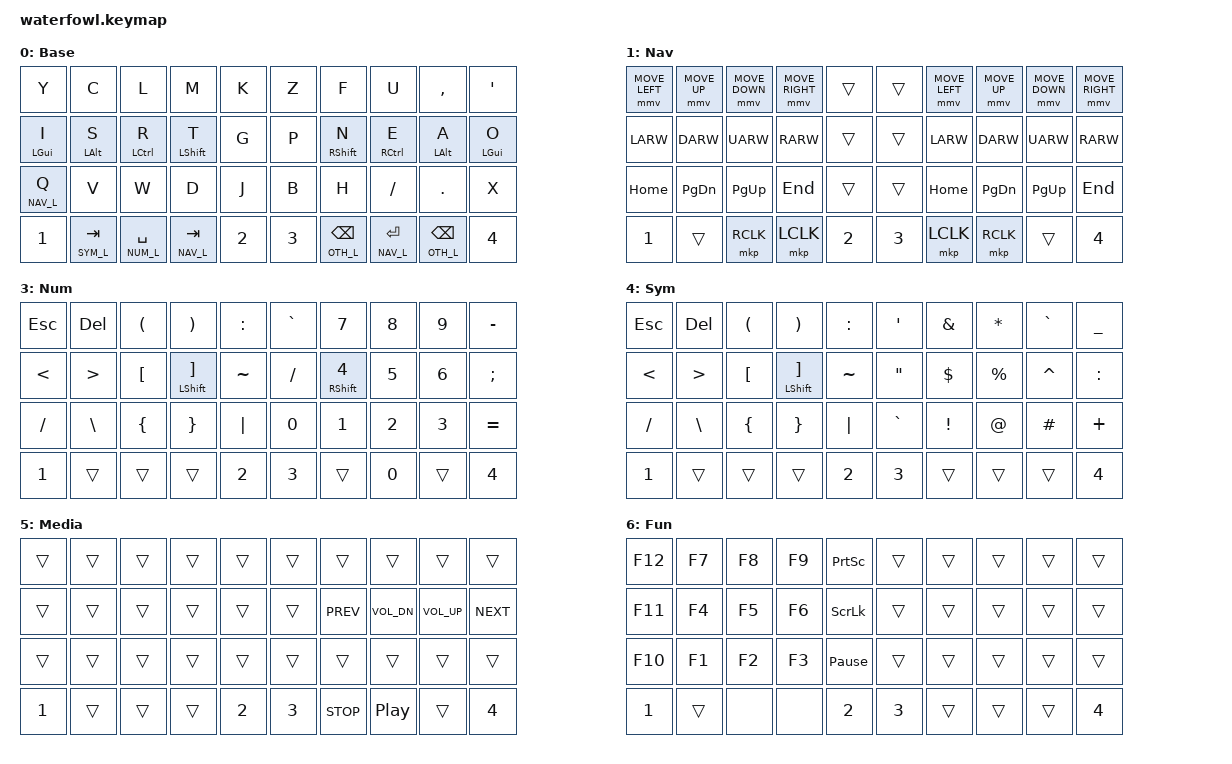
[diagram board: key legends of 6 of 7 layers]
/*
 * Copyright (c) 2022 The ZMK Contributors
 *
 * SPDX-License-Identifier: MIT
 */

#include <behaviors.dtsi>
#include <dt-bindings/zmk/keys.h>
#include <dt-bindings/zmk/bt.h>
#include <dt-bindings/zmk/outputs.h>
#include <dt-bindings/zmk/ext_power.h>
#include <dt-bindings/zmk/mouse.h>

#define NAV_L 1
#define OTH_L 2
#define NUM_L 3
#define SYM_L 4
#define MED_L 5
#define FUN_L 6

// Using layer taps on thumbs, having quick tap as well helps w/ repeating space/backspace
&lt { quick_tap_ms = <200>; };

/ {
    combos {
        compatible = "zmk,combos";

        med_mo {
	    timeout-ms = <50>;
            key-positions = <30 31>;
            bindings = <&caps_word>;
        };

        fn_mo {
	    timeout-ms = <50>;
            key-positions = <32 33>;
            bindings = <&mo FUN_L>;
        };

    };

    behaviors {
        hm: homerow_mods {
            compatible = "zmk,behavior-hold-tap";
            label = "homerow mods";
            #binding-cells = <2>;
            tapping_term_ms = <200>;
            flavor = "tap-preferred";
            bindings = <&kp>, <&kp>;
        };
    };

    keymap {
        compatible = "zmk,keymap";

        default_layer {
                label = "Base";
/* QWERTY
 *
 * ,----------------------------------.                      ,----------------------------------.
 * |   Q  |   W  |   E  |   R  |   T  |                      |   Y  |   U  |   I  |   O  |   P  |
 * |------+------+------+------+------|                      |------+------+------+------+------|
 * |   A  |   S  |   D  |   F  |   G  |                      |   H  |   J  |   K  |   L  |   ;  |
 * |------+------+------+------+------|  ,-----.    ,-----.  |------+------+------+------+------|
 * |   Z  |   X  |   C  |   V  |   B  |  |  2  |    |  3  |  |   N  |   M  |   ,  |   .  |   /  |
 * `----------------------------------'  `-----'    `-----'  `----------------------------------'
 *          ,-----.   ,--------------------.            ,--------------------.   ,-----.
 *          |  1  |   | DEL | SPACE | TAB  |            |  ESC  | BS | ENTER |   |  4  |
 *          `-----'   `--------------------'            `--------------------'   `-----'
 */
            bindings = <
                &kp Y         &kp C      &kp L       &kp M          &kp K         &kp Z            &kp F          &kp U       &kp COMMA  &kp SQT
                &hm LGUI I    &hm LALT S &hm LCTRL R &hm LSHFT T    &kp G         &kp P            &hm RSHFT N    &hm RCTRL E &hm LALT A &hm LGUI O
                &hm NAV_L Q   &kp V      &kp W       &kp D          &kp J         &kp B            &kp H          &kp FSLH    &kp DOT    &kp X
                &kp N1        &lt SYM_L TAB   &lt NUM_L SPACE  &lt NAV_L TAB &kp N2 &kp N3 &lt OTH_L BKSP  &lt NAV_L RET   &lt OTH_L BKSP &kp N4
            >;
            sensor-bindings = <&inc_dec_kp PAGE_UP PAGE_DOWN &inc_dec_kp TAB LS(TAB)>;
        };
        nav_layer {
                label = "Nav";
            bindings = <
                &mmv MOVE_LEFT  &mmv MOVE_UP  &mmv MOVE_DOWN  &mmv MOVE_RIGHT  &trans       &trans    &mmv MOVE_LEFT   &mmv MOVE_UP   &mmv MOVE_DOWN  &mmv MOVE_RIGHT
                &kp LARW        &kp DARW      &kp UARW        &kp RARW         &trans       &trans    &kp LARW         &kp DARW       &kp UARW        &kp RARW
                &kp HOME        &kp PG_DN     &kp PG_UP       &kp END          &trans       &trans    &kp HOME         &kp PG_DN      &kp PG_UP       &kp END
                &kp N1          &trans        &mkp RCLK       &mkp LCLK        &kp N2       &kp N3    &mkp LCLK        &mkp RCLK      &trans          &kp N4
            >;
            sensor-bindings = <&inc_dec_kp PAGE_UP PAGE_DOWN &inc_dec_kp TAB LS(TAB)>;
        };
        other_layer {
            label = "Other";
            bindings = <
                &ext_power EP_ON      &trans     &trans      &trans          &trans       &trans       &trans         &trans       &trans       &bt BT_CLR
                &ext_power EP_OFF     &trans     &trans      &trans          &trans       &trans           &trans         &trans       &trans       &trans
                &ext_power EP_TOG     &trans     &trans      &trans          &trans       &bt BT_SEL 0     &bt BT_SEL 1   &bt BT_SEL 2 &bt BT_SEL 3 &bt BT_SEL 4
                &kp N1     &trans      &trans          &trans   &kp N2       &kp N3    &trans           &trans         &trans
            >;
        };
        num_layer {
            label = "Num";
            bindings = <
                &kp ESC   &kp DEL    &kp LPAR      &kp RPAR         &kp COLON     &kp GRAVE        &kp N7         &kp N8      &kp N9     &kp MINUS
                &kp LT    &kp GT     &kp LBKT      &hm LSHFT RBKT   &kp TILDE     &kp FSLH         &hm RSHFT N4   &kp N5      &kp N6     &kp SEMI
                &kp FSLH  &kp BSLH   &kp LBRC      &kp RBRC         &kp PIPE      &kp N0           &kp N1         &kp N2      &kp N3     &kp EQUAL
                &kp N1    &trans         &trans           &trans    &kp N2       &kp N3    &trans         &kp N0        &trans  &kp N4
            >;
            sensor-bindings = <&inc_dec_kp PAGE_UP PAGE_DOWN &inc_dec_kp TAB LS(TAB)>;
        };

        sym_layer {
            label = "Sym";
            bindings = <
                &kp ESC   &kp DEL     &kp LPAR      &kp RPAR         &kp COLON        &kp SQT   &kp AMPS  &kp STAR   &kp GRAVE  &kp UNDER
                &kp LT    &kp GT      &kp LBKT      &hm LSHFT RBKT   &kp TILDE        &kp DQT   &kp DLLR  &kp PRCNT  &kp CARET  &kp COLON
                &kp FSLH  &kp BSLH    &kp LBRC      &kp RBRC         &kp PIPE         &kp GRAVE &kp EXCL  &kp AT     &kp HASH   &kp PLUS
                &kp N1    &trans      &trans        &trans    &kp N2       &kp N3     &trans    &trans        &trans  &kp N4
            >;
            sensor-bindings = <&inc_dec_kp PAGE_UP PAGE_DOWN &inc_dec_kp TAB LS(TAB)>;
        };

        media_layer {
            label = "Media";
            bindings = <
                &trans	   &trans     &trans      &trans          &trans       &trans           &trans         &trans       &trans       &trans
                &trans     &trans     &trans      &trans          &trans       &trans           &kp C_PREV     &kp C_VOL_DN &kp C_VOL_UP &kp C_NEXT
                &trans     &trans     &trans      &trans          &trans       &trans           &trans         &trans       &trans       &trans
                &kp N1     &trans       &trans          &trans    &kp N2       &kp N3   &kp C_STOP       &kp C_PLAY_PAUSE        &trans  &kp N4
            >;
            sensor-bindings = <&inc_dec_kp PAGE_UP PAGE_DOWN &inc_dec_kp TAB LS(TAB)>;
        };

        fun_layer {
            label = "Fun";
            bindings = <
                &kp F12     &kp F7     &kp F8      &kp F9     &kp PSCRN         &trans          &trans         &trans      &trans     &trans
                &kp F11     &kp F4     &kp F5      &kp F6     &kp SLCK          &trans          &trans         &trans      &trans     &trans
                &kp F10     &kp F1     &kp F2      &kp F3     &kp PAUSE_BREAK   &trans          &trans         &trans      &trans     &trans
                &kp N1      &trans       &none      &none      &kp N2       &kp N3       &trans          &trans          &trans  &kp N4
            >;
            sensor-bindings = <&inc_dec_kp PAGE_UP PAGE_DOWN &inc_dec_kp TAB LS(TAB)>;
        };
    };
};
